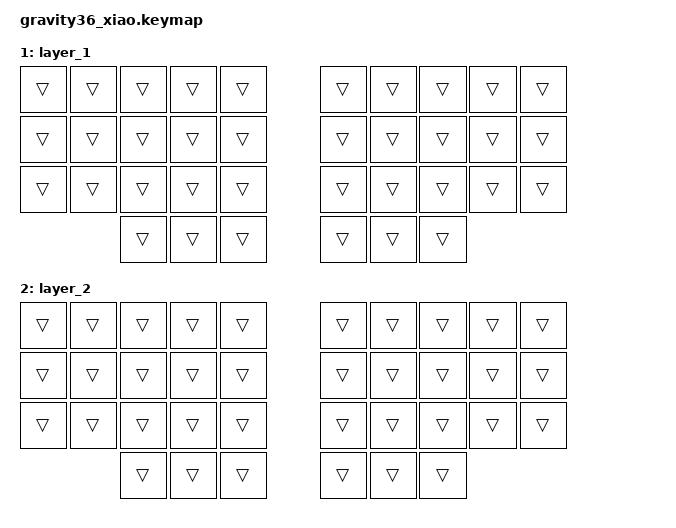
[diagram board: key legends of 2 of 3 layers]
#define RGBLED_WIDGET_COLOR_BLACK   0
#define RGBLED_WIDGET_COLOR_RED     1
#define RGBLED_WIDGET_COLOR_GREEN   2
#define RGBLED_WIDGET_COLOR_YELLOW  3
#define RGBLED_WIDGET_COLOR_BLUE    4
#define RGBLED_WIDGET_COLOR_MAGENTA 5
#define RGBLED_WIDGET_COLOR_CYAN    6
#define RGBLED_WIDGET_COLOR_WHITE   7

#include <behaviors.dtsi>
#include <dt-bindings/zmk/keys.h>

/ {
    aliases {
        led-red = &led0;
        led-green = &led1;
        led-blue = &led2;
    };
};

/ {
    keymap {
        compatible = "zmk,keymap";
        default_layer {
            bindings = <
            /* 左手 */                                          /* 右手 */
            &kp Q   &kp W   &kp E   &kp R   &kp T       &kp Y   &kp U   &kp I   &kp O   &kp P
            &kp A   &kp S   &kp D   &kp F   &kp G       &kp H   &kp J   &kp K   &kp L   &kp SCLN
            &kp Z   &kp X   &kp C   &kp V   &kp B       &kp N   &kp M   &kp CMMA&kp DOT &kp FSLH
            
            /* 4行目：SPACEホールドでLayer1 / ENTERホールドでLayer2 */
            /*        &kp LALT &lt 1 SPC &kp INT_MUHENKAN   &kp INT_HENKAN &lt 2 RET &kp RCTRL    */

            /*    debug用    */
            &kp 1   &kp 2   &kp 3   &kp 4   &kp 5        &kp 6   &kp 7   &kp 8   &kp 9   &kp 0
            >;
        };

        // レイヤー1: SPACE長押し時に有効化（数字や記号など）
        layer_1 {
            bindings = <
            &trans  &trans  &trans  &trans  &trans      &trans  &trans  &trans  &trans  &trans
            &trans  &trans  &trans  &trans  &trans      &trans  &trans  &trans  &trans  &trans
            &trans  &trans  &trans  &trans  &trans      &trans  &trans  &trans  &trans  &trans
                    &trans  &trans  &trans              &trans  &trans  &trans
            >;
        };

        // レイヤー2: ENTER長押し時に有効化（ナビゲーションやファンクションなど）
        layer_2 {
            bindings = <
            &trans  &trans  &trans  &trans  &trans      &trans  &trans  &trans  &trans  &trans
            &trans  &trans  &trans  &trans  &trans      &trans  &trans  &trans  &trans  &trans
            &trans  &trans  &trans  &trans  &trans      &trans  &trans  &trans  &trans  &trans
                    &trans  &trans  &trans              &trans  &trans  &trans
            >;
        };
    };
};
